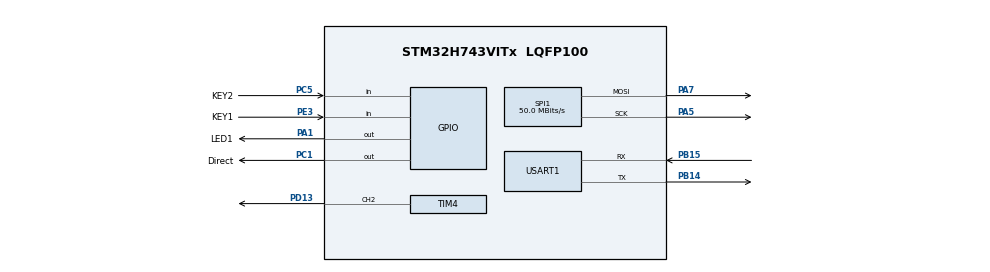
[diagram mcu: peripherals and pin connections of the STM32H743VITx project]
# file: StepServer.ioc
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Dma.Request0=USART1_RX
Dma.Request1=SPI1_TX
Dma.SPI1_TX.1.Direction=DMA_MEMORY_TO_PERIPH
Dma.SPI1_TX.1.EventEnable=DISABLE
Dma.SPI1_TX.1.FIFOMode=DMA_FIFOMODE_DISABLE
Dma.SPI1_TX.1.Instance=DMA1_Stream1
Dma.SPI1_TX.1.MemDataAlignment=DMA_MDATAALIGN_BYTE
Dma.SPI1_TX.1.MemInc=DMA_MINC_ENABLE
Dma.SPI1_TX.1.Mode=DMA_NORMAL
Dma.SPI1_TX.1.PeriphDataAlignment=DMA_PDATAALIGN_BYTE
Dma.SPI1_TX.1.PeriphInc=DMA_PINC_DISABLE
Dma.SPI1_TX.1.Polarity=HAL_DMAMUX_REQ_GEN_RISING
Dma.SPI1_TX.1.Priority=DMA_PRIORITY_LOW
Dma.SPI1_TX.1.RequestNumber=1
Dma.SPI1_TX.1.SignalID=NONE
Dma.SPI1_TX.1.SyncEnable=DISABLE
Dma.SPI1_TX.1.SyncPolarity=HAL_DMAMUX_SYNC_NO_EVENT
Dma.SPI1_TX.1.SyncRequestNumber=1
Dma.SPI1_TX.1.SyncSignalID=NONE
Dma.USART1_RX.0.Direction=DMA_PERIPH_TO_MEMORY
Dma.USART1_RX.0.EventEnable=DISABLE
Dma.USART1_RX.0.FIFOMode=DMA_FIFOMODE_DISABLE
Dma.USART1_RX.0.Instance=DMA1_Stream0
Dma.USART1_RX.0.MemDataAlignment=DMA_MDATAALIGN_BYTE
Dma.USART1_RX.0.MemInc=DMA_MINC_ENABLE
Dma.USART1_RX.0.Mode=DMA_NORMAL
Dma.USART1_RX.0.PeriphDataAlignment=DMA_PDATAALIGN_BYTE
Dma.USART1_RX.0.PeriphInc=DMA_PINC_DISABLE
Dma.USART1_RX.0.Polarity=HAL_DMAMUX_REQ_GEN_RISING
Dma.USART1_RX.0.Priority=DMA_PRIORITY_LOW
Dma.USART1_RX.0.RequestNumber=1
Dma.USART1_RX.0.SignalID=NONE
Dma.USART1_RX.0.SyncEnable=DISABLE
Dma.USART1_RX.0.SyncPolarity=HAL_DMAMUX_SYNC_NO_EVENT
Dma.USART1_RX.0.SyncRequestNumber=1
Dma.USART1_RX.0.SyncSignalID=NONE
FREERTOS.Tasks01=defaultTask,0,128,StartDefaultTask,Default,NULL,Dynamic,NULL,NULL
FREERTOS.configENABLE_FPU=1
Mcu.Family=STM32H7
Mcu.Name=STM32H743VITx
Mcu.Package=LQFP100
NVIC.DMA1_Stream0_IRQn=true\:5\:0\:false\:false\:true\:true\:false\:true\:true
NVIC.DMA1_Stream1_IRQn=true\:5\:0\:false\:false\:true\:true\:false\:true\:true
NVIC.PriorityGroup=NVIC_PRIORITYGROUP_4
NVIC.SPI1_IRQn=true\:5\:0\:false\:false\:true\:true\:false\:true\:true
NVIC.TIM4_IRQn=true\:5\:0\:false\:false\:true\:true\:true\:true\:true
PA1.GPIO_Label=LED1
PA1.Signal=GPIO_Output
PA13\ (JTMS/SWDIO).Mode=Serial_Wire
PA13\ (JTMS/SWDIO).Signal=DEBUG_JTMS-SWDIO
PA14\ (JTCK/SWCLK).Mode=Serial_Wire
PA14\ (JTCK/SWCLK).Signal=DEBUG_JTCK-SWCLK
PA5.Mode=TX_Only_Simplex_Unidirect_Master
PA5.Signal=SPI1_SCK
PA7.Mode=TX_Only_Simplex_Unidirect_Master
PA7.Signal=SPI1_MOSI
PB14.Mode=Asynchronous
PB14.Signal=USART1_TX
PB15.Mode=Asynchronous
PB15.Signal=USART1_RX
PC1.GPIO_Label=Direct
PC1.Signal=GPIO_Output
PC5.GPIO_Label=KEY2
PC5.GPIO_PuPd=GPIO_PULLUP
PC5.Signal=GPIO_Input
PD13.Signal=S_TIM4_CH2
PE3.GPIO_Label=KEY1
PE3.GPIO_PuPd=GPIO_PULLUP
PE3.Signal=GPIO_Input
PH0-OSC_IN\ (PH0).Mode=HSE-External-Oscillator
PH0-OSC_IN\ (PH0).Signal=RCC_OSC_IN
PH1-OSC_OUT\ (PH1).Mode=HSE-External-Oscillator
PH1-OSC_OUT\ (PH1).Signal=RCC_OSC_OUT
ProjectManager.HeapSize=0x200
ProjectManager.StackSize=0x400
ProjectManager.TargetToolchain=STM32CubeIDE
RCC.ADCFreq_Value=50390625
RCC.APB1Freq_Value=100000000
RCC.APB2Freq_Value=100000000
RCC.APB3Freq_Value=100000000
RCC.APB4Freq_Value=100000000
RCC.CortexFreq_Value=400000000
RCC.D1PPRE=RCC_APB3_DIV2
RCC.D2PPRE1=RCC_APB1_DIV2
RCC.D2PPRE2=RCC_APB2_DIV2
RCC.D3PPRE=RCC_APB4_DIV2
RCC.DIVM1=2
RCC.DIVN1=64
RCC.DIVQ1=8
RCC.HCLKFreq_Value=200000000
RCC.HPRE=RCC_HCLK_DIV2
RCC.PLLSourceVirtual=RCC_PLLSOURCE_HSE
RCC.ProductRev=revV
RCC.SYSCLKFreq_VALUE=400000000
RCC.SYSCLKSource=RCC_SYSCLKSOURCE_PLLCLK
RCC.USBFreq_Value=100000000
SH.S_TIM4_CH2.0=TIM4_CH2,PWM Generation2 CH2
SPI1.BaudRatePrescaler=SPI_BAUDRATEPRESCALER_2
SPI1.CLKPhase=SPI_PHASE_1EDGE
SPI1.CLKPolarity=SPI_POLARITY_LOW
SPI1.CalculateBaudRate=50.0 MBits/s
SPI1.DataSize=SPI_DATASIZE_8BIT
SPI1.Direction=SPI_DIRECTION_2LINES_TXONLY
SPI1.Mode=SPI_MODE_MASTER
SPI1.VirtualType=VM_MASTER
TIM4.Channel-PWM\ Generation2\ CH2=TIM_CHANNEL_2
TIM4.Period=100
TIM4.Prescaler=10000
USART1.VirtualMode-Asynchronous=VM_ASYNC
VP_FREERTOS_VS_CMSIS_V1.Mode=CMSIS_V1
board=custom

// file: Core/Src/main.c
/* USER CODE BEGIN Header */
/**
  ******************************************************************************
  * @file           : main.c
  * @brief          : Main program body
  ******************************************************************************
  * @attention
  *
  * Copyright (c) 2023 STMicroelectronics.
  * All rights reserved.
  *
  * This software is licensed under terms that can be found in the LICENSE file
  * in the root directory of this software component.
  * If no LICENSE file comes with this software, it is provided AS-IS.
  *
  ******************************************************************************
  */
/* USER CODE END Header */
#include "main.h"
#include "cmsis_os.h"

SPI_HandleTypeDef hspi1;
DMA_HandleTypeDef hdma_spi1_tx;

TIM_HandleTypeDef htim4;

UART_HandleTypeDef huart1;
DMA_HandleTypeDef hdma_usart1_rx;

osThreadId defaultTaskHandle;

void SystemClock_Config(void);
static void MX_GPIO_Init(void);
static void MX_DMA_Init(void);
static void MX_USART1_UART_Init(void);
static void MX_SPI1_Init(void);
static void MX_TIM4_Init(void);
void StartDefaultTask(void const * argument);

int main(void)
{

  /* MCU Configuration--------------------------------------------------------*/

  /* Reset of all peripherals, Initializes the Flash interface and the Systick. */
  HAL_Init();

  /* Configure the system clock */
  SystemClock_Config();

  /* Initialize all configured peripherals */
  MX_GPIO_Init();
  MX_DMA_Init();
  MX_USART1_UART_Init();
  MX_SPI1_Init();
  MX_TIM4_Init();

  /* Create the thread(s) */
  /* definition and creation of defaultTask */
  osThreadDef(defaultTask, StartDefaultTask, osPriorityNormal, 0, 128);
  defaultTaskHandle = osThreadCreate(osThread(defaultTask), NULL);

  /* Start scheduler */
  osKernelStart();
  /* We should never get here as control is now taken by the scheduler */
  /* Infinite loop */
  while (1)
  {

  }
}

void SystemClock_Config(void)
{
  RCC_OscInitTypeDef RCC_OscInitStruct = {0};
  RCC_ClkInitTypeDef RCC_ClkInitStruct = {0};

  /** Supply configuration update enable
  */
  HAL_PWREx_ConfigSupply(PWR_LDO_SUPPLY);

  /** Configure the main internal regulator output voltage
  */
  __HAL_PWR_VOLTAGESCALING_CONFIG(PWR_REGULATOR_VOLTAGE_SCALE1);

  while(!__HAL_PWR_GET_FLAG(PWR_FLAG_VOSRDY)) {}

  /** Initializes the RCC Oscillators according to the specified parameters
  * in the RCC_OscInitTypeDef structure.
  */
  RCC_OscInitStruct.OscillatorType = RCC_OSCILLATORTYPE_HSE;
  RCC_OscInitStruct.HSEState = RCC_HSE_ON;
  RCC_OscInitStruct.PLL.PLLState = RCC_PLL_ON;
  RCC_OscInitStruct.PLL.PLLSource = RCC_PLLSOURCE_HSE;
  RCC_OscInitStruct.PLL.PLLM = 2;
  RCC_OscInitStruct.PLL.PLLN = 64;
  RCC_OscInitStruct.PLL.PLLP = 2;
  RCC_OscInitStruct.PLL.PLLQ = 8;
  RCC_OscInitStruct.PLL.PLLR = 2;
  RCC_OscInitStruct.PLL.PLLRGE = RCC_PLL1VCIRANGE_3;
  RCC_OscInitStruct.PLL.PLLVCOSEL = RCC_PLL1VCOWIDE;
  RCC_OscInitStruct.PLL.PLLFRACN = 0;
  if (HAL_RCC_OscConfig(&RCC_OscInitStruct) != HAL_OK)
  {
    Error_Handler();
  }

  /** Initializes the CPU, AHB and APB buses clocks
  */
  RCC_ClkInitStruct.ClockType = RCC_CLOCKTYPE_HCLK|RCC_CLOCKTYPE_SYSCLK
                              |RCC_CLOCKTYPE_PCLK1|RCC_CLOCKTYPE_PCLK2
                              |RCC_CLOCKTYPE_D3PCLK1|RCC_CLOCKTYPE_D1PCLK1;
  RCC_ClkInitStruct.SYSCLKSource = RCC_SYSCLKSOURCE_PLLCLK;
  RCC_ClkInitStruct.SYSCLKDivider = RCC_SYSCLK_DIV1;
  RCC_ClkInitStruct.AHBCLKDivider = RCC_HCLK_DIV2;
  RCC_ClkInitStruct.APB3CLKDivider = RCC_APB3_DIV2;
  RCC_ClkInitStruct.APB1CLKDivider = RCC_APB1_DIV2;
  RCC_ClkInitStruct.APB2CLKDivider = RCC_APB2_DIV2;
  RCC_ClkInitStruct.APB4CLKDivider = RCC_APB4_DIV2;

  if (HAL_RCC_ClockConfig(&RCC_ClkInitStruct, FLASH_LATENCY_2) != HAL_OK)
  {
    Error_Handler();
  }
}

static void MX_SPI1_Init(void)
{

  /* SPI1 parameter configuration*/
  hspi1.Instance = SPI1;
  hspi1.Init.Mode = SPI_MODE_MASTER;
  hspi1.Init.Direction = SPI_DIRECTION_2LINES_TXONLY;
  hspi1.Init.DataSize = SPI_DATASIZE_8BIT;
  hspi1.Init.CLKPolarity = SPI_POLARITY_LOW;
  hspi1.Init.CLKPhase = SPI_PHASE_1EDGE;
  hspi1.Init.NSS = SPI_NSS_SOFT;
  hspi1.Init.BaudRatePrescaler = SPI_BAUDRATEPRESCALER_2;
  hspi1.Init.FirstBit = SPI_FIRSTBIT_MSB;
  hspi1.Init.TIMode = SPI_TIMODE_DISABLE;
  hspi1.Init.CRCCalculation = SPI_CRCCALCULATION_DISABLE;
  hspi1.Init.CRCPolynomial = 0x0;
  hspi1.Init.NSSPMode = SPI_NSS_PULSE_ENABLE;
  hspi1.Init.NSSPolarity = SPI_NSS_POLARITY_LOW;
  hspi1.Init.FifoThreshold = SPI_FIFO_THRESHOLD_01DATA;
  hspi1.Init.TxCRCInitializationPattern = SPI_CRC_INITIALIZATION_ALL_ZERO_PATTERN;
  hspi1.Init.RxCRCInitializationPattern = SPI_CRC_INITIALIZATION_ALL_ZERO_PATTERN;
  hspi1.Init.MasterSSIdleness = SPI_MASTER_SS_IDLENESS_00CYCLE;
  hspi1.Init.MasterInterDataIdleness = SPI_MASTER_INTERDATA_IDLENESS_00CYCLE;
  hspi1.Init.MasterReceiverAutoSusp = SPI_MASTER_RX_AUTOSUSP_DISABLE;
  hspi1.Init.MasterKeepIOState = SPI_MASTER_KEEP_IO_STATE_DISABLE;
  hspi1.Init.IOSwap = SPI_IO_SWAP_DISABLE;
  if (HAL_SPI_Init(&hspi1) != HAL_OK)
  {
    Error_Handler();
  }

}

static void MX_TIM4_Init(void)
{

  TIM_MasterConfigTypeDef sMasterConfig = {0};
  TIM_OC_InitTypeDef sConfigOC = {0};

  htim4.Instance = TIM4;
  htim4.Init.Prescaler = 10000;
  htim4.Init.CounterMode = TIM_COUNTERMODE_UP;
  htim4.Init.Period = 100;
  htim4.Init.ClockDivision = TIM_CLOCKDIVISION_DIV1;
  htim4.Init.AutoReloadPreload = TIM_AUTORELOAD_PRELOAD_DISABLE;
  if (HAL_TIM_PWM_Init(&htim4) != HAL_OK)
  {
    Error_Handler();
  }
  sMasterConfig.MasterOutputTrigger = TIM_TRGO_RESET;
  sMasterConfig.MasterSlaveMode = TIM_MASTERSLAVEMODE_DISABLE;
  if (HAL_TIMEx_MasterConfigSynchronization(&htim4, &sMasterConfig) != HAL_OK)
  {
    Error_Handler();
  }
  sConfigOC.OCMode = TIM_OCMODE_PWM1;
  sConfigOC.Pulse = 0;
  sConfigOC.OCPolarity = TIM_OCPOLARITY_HIGH;
  sConfigOC.OCFastMode = TIM_OCFAST_DISABLE;
  if (HAL_TIM_PWM_ConfigChannel(&htim4, &sConfigOC, TIM_CHANNEL_2) != HAL_OK)
  {
    Error_Handler();
  }
  HAL_TIM_MspPostInit(&htim4);

}

static void MX_USART1_UART_Init(void)
{

  huart1.Instance = USART1;
  huart1.Init.BaudRate = 115200;
  huart1.Init.WordLength = UART_WORDLENGTH_8B;
  huart1.Init.StopBits = UART_STOPBITS_1;
  huart1.Init.Parity = UART_PARITY_NONE;
  huart1.Init.Mode = UART_MODE_TX_RX;
  huart1.Init.HwFlowCtl = UART_HWCONTROL_NONE;
  huart1.Init.OverSampling = UART_OVERSAMPLING_16;
  huart1.Init.OneBitSampling = UART_ONE_BIT_SAMPLE_DISABLE;
  huart1.Init.ClockPrescaler = UART_PRESCALER_DIV1;
  huart1.AdvancedInit.AdvFeatureInit = UART_ADVFEATURE_NO_INIT;
  if (HAL_UART_Init(&huart1) != HAL_OK)
  {
    Error_Handler();
  }
  if (HAL_UARTEx_SetTxFifoThreshold(&huart1, UART_TXFIFO_THRESHOLD_1_8) != HAL_OK)
  {
    Error_Handler();
  }
  if (HAL_UARTEx_SetRxFifoThreshold(&huart1, UART_RXFIFO_THRESHOLD_1_8) != HAL_OK)
  {
    Error_Handler();
  }
  if (HAL_UARTEx_DisableFifoMode(&huart1) != HAL_OK)
  {
    Error_Handler();
  }

}

static void MX_DMA_Init(void)
{

  /* DMA controller clock enable */
  __HAL_RCC_DMA1_CLK_ENABLE();

  /* DMA interrupt init */
  /* DMA1_Stream0_IRQn interrupt configuration */
  HAL_NVIC_SetPriority(DMA1_Stream0_IRQn, 5, 0);
  HAL_NVIC_EnableIRQ(DMA1_Stream0_IRQn);
  /* DMA1_Stream1_IRQn interrupt configuration */
  HAL_NVIC_SetPriority(DMA1_Stream1_IRQn, 5, 0);
  HAL_NVIC_EnableIRQ(DMA1_Stream1_IRQn);

}

static void MX_GPIO_Init(void)
{
  GPIO_InitTypeDef GPIO_InitStruct = {0};

  /* GPIO Ports Clock Enable */
  __HAL_RCC_GPIOE_CLK_ENABLE();
  __HAL_RCC_GPIOH_CLK_ENABLE();
  __HAL_RCC_GPIOC_CLK_ENABLE();
  __HAL_RCC_GPIOA_CLK_ENABLE();
  __HAL_RCC_GPIOB_CLK_ENABLE();
  __HAL_RCC_GPIOD_CLK_ENABLE();

  /*Configure GPIO pin Output Level */
  HAL_GPIO_WritePin(Direct_GPIO_Port, Direct_Pin, GPIO_PIN_RESET);

  /*Configure GPIO pin Output Level */
  HAL_GPIO_WritePin(LED1_GPIO_Port, LED1_Pin, GPIO_PIN_RESET);

  /*Configure GPIO pin : KEY1_Pin */
  GPIO_InitStruct.Pin = KEY1_Pin;
  GPIO_InitStruct.Mode = GPIO_MODE_INPUT;
  GPIO_InitStruct.Pull = GPIO_PULLUP;
  HAL_GPIO_Init(KEY1_GPIO_Port, &GPIO_InitStruct);

  /*Configure GPIO pin : Direct_Pin */
  GPIO_InitStruct.Pin = Direct_Pin;
  GPIO_InitStruct.Mode = GPIO_MODE_OUTPUT_PP;
  GPIO_InitStruct.Pull = GPIO_NOPULL;
  GPIO_InitStruct.Speed = GPIO_SPEED_FREQ_LOW;
  HAL_GPIO_Init(Direct_GPIO_Port, &GPIO_InitStruct);

  /*Configure GPIO pin : LED1_Pin */
  GPIO_InitStruct.Pin = LED1_Pin;
  GPIO_InitStruct.Mode = GPIO_MODE_OUTPUT_PP;
  GPIO_InitStruct.Pull = GPIO_NOPULL;
  GPIO_InitStruct.Speed = GPIO_SPEED_FREQ_LOW;
  HAL_GPIO_Init(LED1_GPIO_Port, &GPIO_InitStruct);

  /*Configure GPIO pin : KEY2_Pin */
  GPIO_InitStruct.Pin = KEY2_Pin;
  GPIO_InitStruct.Mode = GPIO_MODE_INPUT;
  GPIO_InitStruct.Pull = GPIO_PULLUP;
  HAL_GPIO_Init(KEY2_GPIO_Port, &GPIO_InitStruct);

}

void StartDefaultTask(void const * argument)
{
  for(;;)
  {
    osDelay(1);
  }
}

void Error_Handler(void)
{
  __disable_irq();
  while (1)
  {
  }
}

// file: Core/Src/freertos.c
/* USER CODE BEGIN Header */
/**
  ******************************************************************************
  * File Name          : freertos.c
  * Description        : Code for freertos applications
  ******************************************************************************
  * @attention
  *
  * Copyright (c) 2023 STMicroelectronics.
  * All rights reserved.
  *
  * This software is licensed under terms that can be found in the LICENSE file
  * in the root directory of this software component.
  * If no LICENSE file comes with this software, it is provided AS-IS.
  *
  ******************************************************************************
  */
/* USER CODE END Header */

#include "FreeRTOS.h"
#include "task.h"
#include "main.h"

/* USER CODE BEGIN FunctionPrototypes */
void MotorTask(void const * argument);

osThreadId MotorControlTaskHandle;
osThreadDef(MotorTask, MotorTask, osPriorityHigh, 0, 512);

/* USER CODE END FunctionPrototypes */

/* GetIdleTaskMemory prototype (linked to static allocation support) */
void vApplicationGetIdleTaskMemory( StaticTask_t **ppxIdleTaskTCBBuffer, StackType_t **ppxIdleTaskStackBuffer, uint32_t *pulIdleTaskStackSize );

/* USER CODE BEGIN GET_IDLE_TASK_MEMORY */
static StaticTask_t xIdleTaskTCBBuffer;
static StackType_t xIdleStack[configMINIMAL_STACK_SIZE];

void vApplicationGetIdleTaskMemory( StaticTask_t **ppxIdleTaskTCBBuffer, StackType_t **ppxIdleTaskStackBuffer, uint32_t *pulIdleTaskStackSize )
{
  *ppxIdleTaskTCBBuffer = &xIdleTaskTCBBuffer;
  *ppxIdleTaskStackBuffer = &xIdleStack[0];
  *pulIdleTaskStackSize = configMINIMAL_STACK_SIZE;
  /* place for user code */
}
/* USER CODE END GET_IDLE_TASK_MEMORY */

/* USER CODE BEGIN Application */
void MotorTask(void const * argument){

    StepMotor_init();

    for(;;)
    {
        osDelay(5);
    }
}
/* USER CODE END Application */
